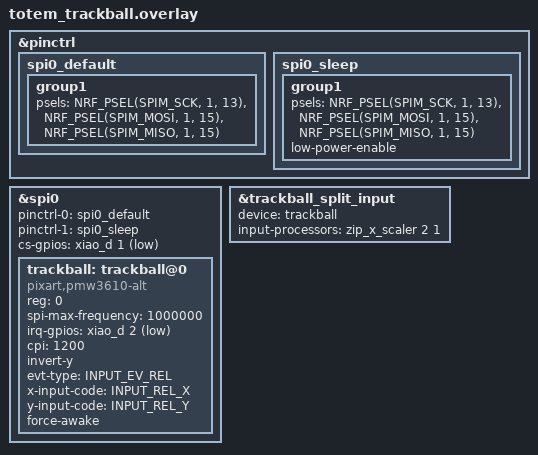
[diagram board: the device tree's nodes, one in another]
#include <dt-bindings/zmk/matrix_transform.h>
#include <zephyr/dt-bindings/input/input-event-codes.h>
#include <input/processors.dtsi>
#include "input-split.dtsi"
#include "totem.dtsi"


&pinctrl {
    spi0_default: spi0_default {
        group1 {
            psels = <NRF_PSEL(SPIM_SCK, 1, 13)>,
                <NRF_PSEL(SPIM_MOSI, 1, 15)>,
                <NRF_PSEL(SPIM_MISO, 1, 15)>;
        };
    };

    spi0_sleep: spi0_sleep {
        group1 {
            psels = <NRF_PSEL(SPIM_SCK, 1, 13)>,
                <NRF_PSEL(SPIM_MOSI, 1, 15)>,
                <NRF_PSEL(SPIM_MISO, 1, 15)>;
            low-power-enable;
        };
    };
};

#include <zephyr/dt-bindings/input/input-event-codes.h>

&spi0 {
    status = "okay";
    pinctrl-0 = <&spi0_default>;
    pinctrl-1 = <&spi0_sleep>;
    pinctrl-names = "default", "sleep";
    cs-gpios = <&xiao_d 1 GPIO_ACTIVE_LOW>;

    trackball: trackball@0 {
		status = "okay";
        compatible = "pixart,pmw3610-alt";
        reg = <0>;
        spi-max-frequency = <1000000>;
        irq-gpios = <&xiao_d 2 (GPIO_ACTIVE_LOW | GPIO_PULL_UP)>;
		cpi = <1200>;

		invert-y;
        evt-type = <INPUT_EV_REL>;
        x-input-code = <INPUT_REL_X>;
        y-input-code = <INPUT_REL_Y>;

        force-awake;
    };
};


&trackball_split_input {
	device = <&trackball>;

	input-processors = <&zip_x_scaler 2 1>;
};

